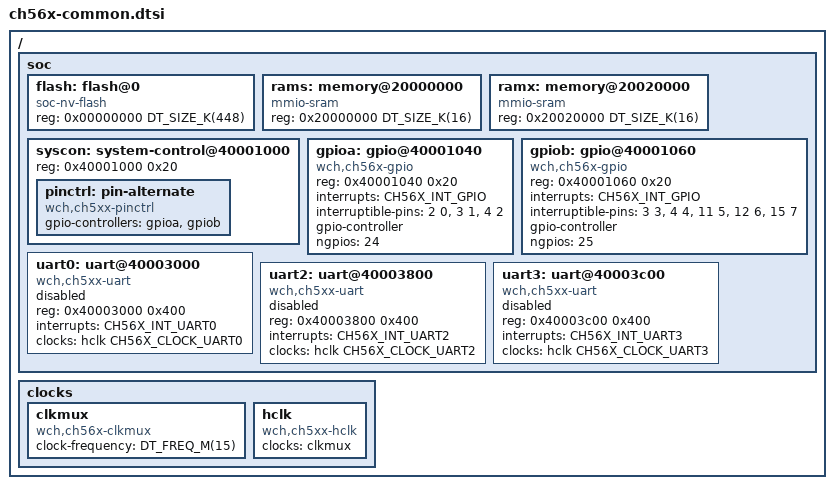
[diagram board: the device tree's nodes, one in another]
/*
 * Copyright (c) 2023 Chen Xingyu <hi@xingrz.me>
 * SPDX-License-Identifier: Apache-2.0
 */

#include <mem.h>
#include <freq.h>

#include <zephyr/dt-bindings/clock/ch56x-clocks.h>
#include <zephyr/dt-bindings/interrupt-controller/ch56x-int.h>

#include <wch/qingke-v3.dtsi>

/ {
	soc {
		flash: flash@0 {
			compatible = "soc-nv-flash";
			reg = <0x00000000 DT_SIZE_K(448)>;
		};

		rams: memory@20000000 {
			compatible = "mmio-sram";
			reg = <0x20000000 DT_SIZE_K(16)>;
		};

		ramx: memory@20020000 {
			compatible = "mmio-sram";
			reg = <0x20020000 DT_SIZE_K(16)>;
		};

		syscon: system-control@40001000 {
			reg = <0x40001000 0x20>;

			pinctrl: pin-alternate {
				compatible = "wch,ch5xx-pinctrl";
				gpio-controllers = <&gpioa>, <&gpiob>;
			};
		};

		gpioa: gpio@40001040 {
			compatible = "wch,ch56x-gpio";
			reg = <0x40001040 0x20>;
			interrupts = <CH56X_INT_GPIO>;
			interruptible-pins = <2 0>, <3 1>, <4 2>;
			gpio-controller;
			#gpio-cells = <2>;
			ngpios = <24>;
		};

		gpiob: gpio@40001060 {
			compatible = "wch,ch56x-gpio";
			reg = <0x40001060 0x20>;
			interrupts = <CH56X_INT_GPIO>;
			interruptible-pins = <3 3>, <4 4>, <11 5>, <12 6>, <15 7>;
			gpio-controller;
			#gpio-cells = <2>;
			ngpios = <25>;
		};

		uart0: uart@40003000 {
			compatible = "wch,ch5xx-uart";
			reg = <0x40003000 0x400>;
			interrupts = <CH56X_INT_UART0>;
			clocks = <&hclk CH56X_CLOCK_UART0>;
			status = "disabled";
		};

		uart2: uart@40003800 {
			compatible = "wch,ch5xx-uart";
			reg = <0x40003800 0x400>;
			interrupts = <CH56X_INT_UART2>;
			clocks = <&hclk CH56X_CLOCK_UART2>;
			status = "disabled";
		};

		uart3: uart@40003c00 {
			compatible = "wch,ch5xx-uart";
			reg = <0x40003c00 0x400>;
			interrupts = <CH56X_INT_UART3>;
			clocks = <&hclk CH56X_CLOCK_UART3>;
			status = "disabled";
		};
	};

	clocks {
		clkmux: clkmux {
			compatible = "wch,ch56x-clkmux";
			clock-frequency = <DT_FREQ_M(15)>;
			#clock-cells = <0>;
		};

		hclk: hclk {
			compatible = "wch,ch5xx-hclk";
			clocks = <&clkmux>;
			#clock-cells = <2>;
		};
	};
};
